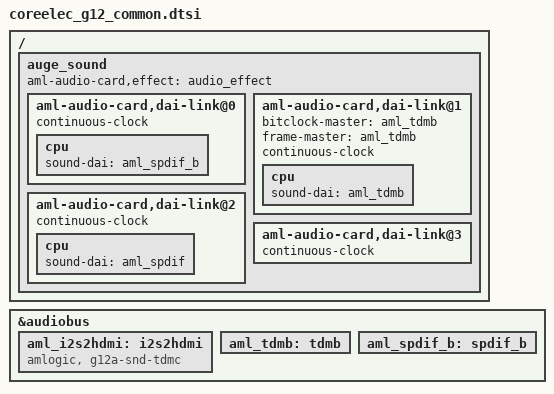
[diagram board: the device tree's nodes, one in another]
#include "coreelec_common.dtsi"

/{
	auge_sound {
		aml-audio-card,effect = <&audio_effect>;

		aml-audio-card,dai-link@0 {
			continuous-clock;
			cpu {
				sound-dai = <&aml_spdif_b>;
			};
		};

		aml-audio-card,dai-link@1 {
			bitclock-master = <&aml_tdmb>;
			frame-master = <&aml_tdmb>;
			continuous-clock;
			cpu {
				sound-dai = <&aml_tdmb>;
			};
		};

		aml-audio-card,dai-link@2 {
			continuous-clock;
			cpu {
				sound-dai = <&aml_spdif>;
			};
		};

		aml-audio-card,dai-link@3 {
			continuous-clock;
		};
	};
};

&audiobus {
	aml_i2s2hdmi: i2s2hdmi {
		compatible = "amlogic, g12a-snd-tdmc";
	};

	aml_tdmb: tdmb {
		/delete-property/ pinctrl-names;
		/delete-property/ pinctrl-0;
		/delete-property/ samesource_sel;
		status = "okay";
	};

	aml_spdif_b: spdif_b {
		status = "okay";
	};
};
